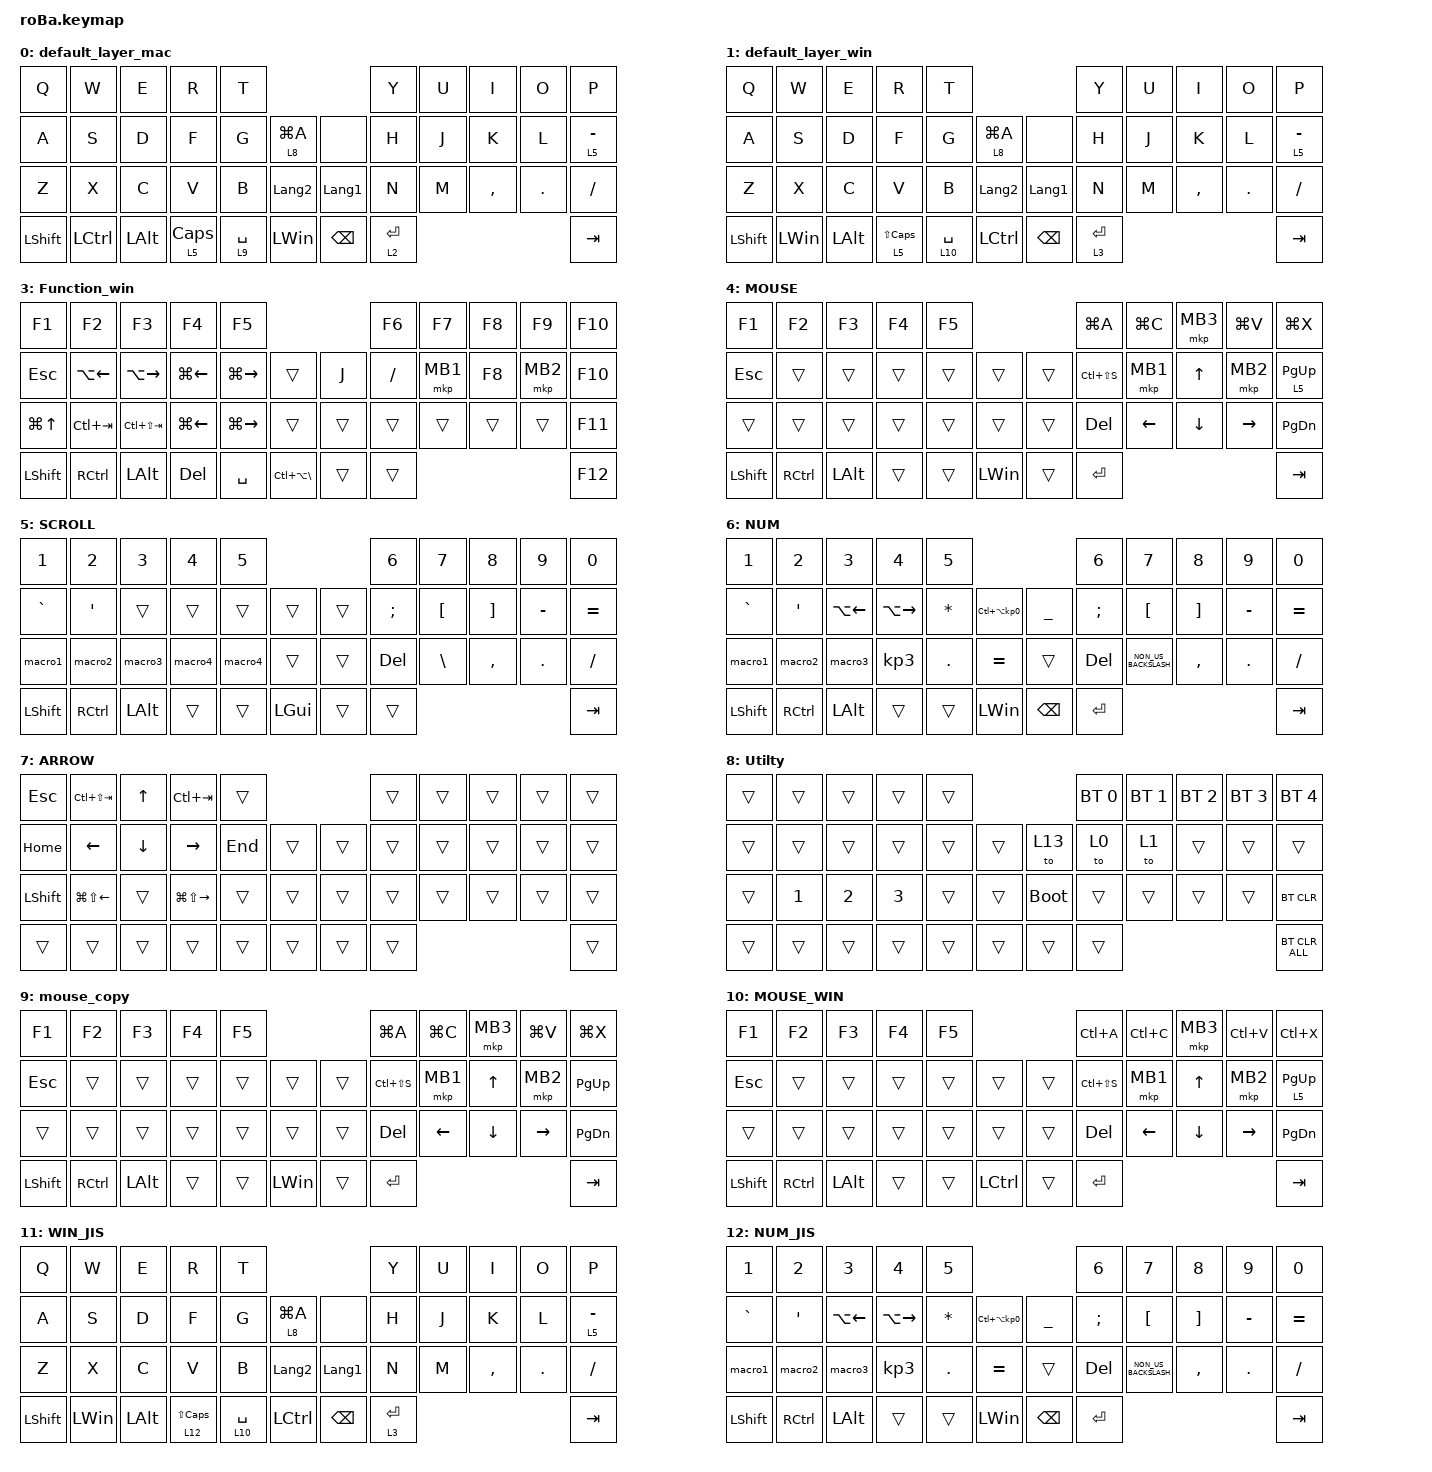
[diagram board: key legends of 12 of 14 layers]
#include <input/processors.dtsi>
#include <behaviors.dtsi>
#include <dt-bindings/zmk/bt.h>
#include <dt-bindings/zmk/keys.h>
#include <dt-bindings/zmk/pointing.h>

&mt {
    flavor = "balanced";
    quick-tap-ms = <0>;
};

&zip_temp_layer { require-prior-idle-ms = <200>; };

&trackball_listener { input-processors = <&zip_temp_layer 4 300>; };

&trackball {
    // automouse-layer = <4>;

    scroll-layers = <5>;

    // arrows {
    //     layers = <3>;
    //     bindings =
    //         <&kp RIGHT_ARROW>,
    //         <&kp LEFT_ARROW>,
    //         <&kp UP_ARROW>,
    //         <&kp DOWN_ARROW>;
    //     tick = <10>;
    //     wait-ms = <5>;
    //     tap-ms = <5>;
    // };
};

/ {
    combos {
        compatible = "zmk,combos";

        tab {
            bindings = <&kp TAB>;
            key-positions = <11 12>;
        };

        shift_tab {
            bindings = <&kp LS(TAB)>;
            key-positions = <12 13>;
        };

        muhennkann {
            bindings = <&to_layer_0 INT_MUHENKAN>;
            key-positions = <11 10>;
        };

        double_quotation {
            bindings = <&kp DOUBLE_QUOTES>;
            key-positions = <20 21>;
        };

        eq {
            bindings = <&kp EQUAL>;
            key-positions = <24 25>;
        };

        JIS_2 {
            bindings = <&kp LEFT_BRACKET>;
            key-positions = <34 1>;
            layers = <12>;
        };

        JIS_3 {
            bindings = <&kp HASH>;
            key-positions = <34 2>;
            layers = <12>;
        };

        JIS_4 {
            bindings = <&kp DOLLAR>;
            key-positions = <34 3>;
            layers = <12>;
        };

        JIS_5 {
            bindings = <&kp PERCENT>;
            key-positions = <34 4>;
            layers = <12>;
        };

        JIS_6 {
            bindings = <&kp EQUAL>;
            key-positions = <34 5>;
            layers = <12>;
        };

        JIS_7 {
            bindings = <&kp CARET>;
            key-positions = <34 6>;
            layers = <12>;
        };

        JIS_8 {
            bindings = <&kp LS(SINGLE_QUOTE)>;
            key-positions = <34 7>;
            layers = <12>;
        };

        JIS_9 {
            bindings = <&kp LS(ASTRK)>;
            key-positions = <34 8>;
            layers = <12>;
        };

        JIS_0 {
            bindings = <&kp LEFT_PARENTHESIS>;
            key-positions = <34 9>;
            layers = <12>;
        };
    };

    macros {
        to_layer_0: to_layer_0 {
            compatible = "zmk,behavior-macro-one-param";
            #binding-cells = <1>;
            bindings = <&to 0 &macro_param_1to1 &kp MACRO_PLACEHOLDER>;
            label = "TO_LAYER_0";
        };

        macro1: macro1 {
            compatible = "zmk,behavior-macro";
            #binding-cells = <0>;
            bindings = <&kp LS(M) &kp O &kp R &kp I &kp H &kp I &kp R &kp O &kp N1 &kp N9 &kp N9 &kp N1>;
            label = "MACRO1";
        };

        macro2: macro2 {
            compatible = "zmk,behavior-macro";
            #binding-cells = <0>;
            bindings = <&kp LS(L) &kp O &kp V &kp E &kp N1 &kp N9 &kp N9 &kp N1 &kp DOT &kp DOT>;
            label = "MACRO2";
        };

        macro3: macro3 {
            compatible = "zmk,behavior-macro";
            #binding-cells = <0>;
            bindings = <&kp L &kp O &kp V &kp E &kp N1 &kp N9 &kp N9 &kp N1>;
            label = "MACRO3";
        };

        macro4: macro4 {
            compatible = "zmk,behavior-macro";
            #binding-cells = <0>;
            bindings = <&kp LS(M) &kp O &kp R &kp I &kp H &kp I &kp R &kp O &kp N1 &kp N9 &kp N9 &kp N1 &kp PERIOD &kp PERIOD>;
            label = "MACRO4";
        };
    };

    behaviors {
        lt_to_layer_0: lt_to_layer_0 {
            compatible = "zmk,behavior-hold-tap";
            label = "LAYER_TAP_TO_0";
            bindings = <&mo>, <&to_layer_0>;

            #binding-cells = <2>;
            tapping-term-ms = <200>;
        };
    };

    keymap {
        compatible = "zmk,keymap";

        default_layer_mac {
            bindings = <
&kp Q           &kp W             &kp E         &kp R       &kp T                                            &kp Y        &kp U  &kp I      &kp O    &kp P
&kp A           &kp S             &kp D         &kp F       &kp G        &lt 8 LG(A)         &none           &kp H        &kp J  &kp K      &kp L    &lt 5 MINUS
&kp Z           &kp X             &kp C         &kp V       &kp B        &kp LANGUAGE_2      &kp LANGUAGE_1  &kp N        &kp M  &kp COMMA  &kp DOT  &kp SLASH
&kp LEFT_SHIFT  &kp LEFT_CONTROL  &kp LEFT_ALT  &lt 5 CAPS  &lt 9 SPACE  &kp LEFT_WIN        &kp BACKSPACE   &lt 2 ENTER                             &kp TAB
            >;

            sensor-bindings = <&inc_dec_kp PAGE_UP PAGE_DOWN>;
        };

        default_layer_win {
            bindings = <
&kp Q           &kp W         &kp E         &kp R           &kp T                                               &kp Y        &kp U  &kp I      &kp O    &kp P
&kp A           &kp S         &kp D         &kp F           &kp G         &lt 8 LG(A)           &none           &kp H        &kp J  &kp K      &kp L    &lt 5 MINUS
&kp Z           &kp X         &kp C         &kp V           &kp B         &kp LANGUAGE_2        &kp LANGUAGE_1  &kp N        &kp M  &kp COMMA  &kp DOT  &kp SLASH
&kp LEFT_SHIFT  &kp LEFT_WIN  &kp LEFT_ALT  &lt 5 LS(CAPS)  &lt 10 SPACE  &kp LEFT_CONTROL      &kp BACKSPACE   &lt 3 ENTER                             &kp TAB
            >;

            sensor-bindings = <&inc_dec_kp PAGE_UP PAGE_DOWN>;
        };

        Function_mac {
            bindings = <
&kp F1                &kp F2            &kp F3             &kp F4         &kp F5                                            &kp F6    &kp F7    &kp F8  &kp F9    &kp F10
&kp ESC               &kp LG(LBKT)      &kp LG(RBKT)       &kp LC(LA(D))  &kp LC(LA(G))  &trans                     &kp J   &kp FSLH  &mkp MB1  &kp F8  &mkp MB2  &kp F10
&kp LA(LC(LS(FSLH)))  &kp LA(LG(LEFT))  &kp LA(LG(RIGHT))  &kp LA(LC(E))  &kp LC(LA(T))  &trans                     &trans  &trans    &trans    &trans  &trans    &kp F11
&kp LSHFT             &kp RCTRL         &kp LEFT_ALT       &kp DELETE     &kp SPACE      &kp LC(LA(BACKSLASH))      &trans  &trans                                &kp F12
            >;
        };

        Function_win {
            bindings = <
&kp F1            &kp F2        &kp F3           &kp F4        &kp F5                                            &kp F6    &kp F7    &kp F8  &kp F9    &kp F10
&kp ESC           &kp LA(LEFT)  &kp LA(RIGHT)    &kp LG(LEFT)  &kp LG(RIGHT)  &trans                     &kp J   &kp FSLH  &mkp MB1  &kp F8  &mkp MB2  &kp F10
&kp LG(UP_ARROW)  &kp LC(TAB)   &kp LC(LS(TAB))  &kp LG(LEFT)  &kp LG(RIGHT)  &trans                     &trans  &trans    &trans    &trans  &trans    &kp F11
&kp LSHFT         &kp RCTRL     &kp LEFT_ALT     &kp DELETE    &kp SPACE      &kp LC(LA(BACKSLASH))      &trans  &trans                                &kp F12
            >;
        };

        MOUSE {
            bindings = <
&kp F1          &kp F2     &kp F3        &kp F4  &kp F5                            &kp LG(A)      &kp LG(C)  &mkp MB3  &kp LG(V)  &kp LG(X)
&kp ESC         &trans     &trans        &trans  &trans  &trans            &trans  &kp LC(LS(S))  &mkp MB1   &kp UP    &mkp MB2   &lt 5 PAGE_UP
&trans          &trans     &trans        &trans  &trans  &trans            &trans  &kp DELETE     &kp LEFT   &kp DOWN  &kp RIGHT  &kp PAGE_DOWN
&kp LEFT_SHIFT  &kp RCTRL  &kp LEFT_ALT  &trans  &trans  &kp LEFT_WIN      &trans  &kp ENTER                                      &kp TAB
            >;
        };

        SCROLL {
            bindings = <
&kp N1     &kp N2     &kp N3        &kp N4   &kp N5                         &kp N6      &kp N7         &kp N8     &kp N9     &kp N0
&kp GRAVE  &kp SQT    &trans        &trans   &trans   &trans        &trans  &kp SEMI    &kp LBKT       &kp RBKT   &kp MINUS  &kp EQUAL
&macro1    &macro2    &macro3       &macro4  &macro4  &trans        &trans  &kp DELETE  &kp BACKSLASH  &kp COMMA  &kp DOT    &kp FSLH
&kp LSHFT  &kp RCTRL  &kp LEFT_ALT  &trans   &trans   &kp LGUI      &trans  &trans                                           &kp TAB
            >;
        };

        NUM {
            bindings = <
&kp NUMBER_1    &kp NUMBER_2  &kp NUMBER_3  &kp NUMBER_4     &kp N5                                                     &kp NUMBER_6   &kp N7                &kp N8             &kp N9      &kp N0
&kp GRAVE       &kp SQT       &kp LA(LEFT)  &kp LA(RIGHT)    &kp ASTERISK  &kp LC(LA(KP_NUMBER_0))      &kp UNDERSCORE  &kp SEMICOLON  &kp LEFT_BRACKET      &kp RIGHT_BRACKET  &kp MINUS   &kp EQUAL
&macro1         &macro2       &macro3       &kp KP_NUMBER_3  &kp PERIOD    &kp EQUAL                    &trans          &kp DEL        &kp NON_US_BACKSLASH  &kp COMMA          &kp PERIOD  &kp SLASH
&kp LEFT_SHIFT  &kp RCTRL     &kp LEFT_ALT  &trans           &trans        &kp LEFT_WIN                 &kp BACKSPACE   &kp ENTER                                                           &kp TAB
            >;
        };

        ARROW {
            bindings = <
&kp ESCAPE      &kp LC(LS(TAB))         &kp UP_ARROW    &kp LC(TAB)              &trans                       &trans  &trans  &trans  &trans  &trans
&kp HOME        &kp LEFT_ARROW          &kp DOWN_ARROW  &kp RIGHT_ARROW          &kp END  &trans      &trans  &trans  &trans  &trans  &trans  &trans
&kp LEFT_SHIFT  &kp LG(LS(LEFT_ARROW))  &trans          &kp LG(LS(RIGHT_ARROW))  &trans   &trans      &trans  &trans  &trans  &trans  &trans  &trans
&trans          &trans                  &trans          &trans                   &trans   &trans      &trans  &trans                          &trans
            >;

            sensor-bindings = <&inc_dec_kp LC(PAGE_UP) LC(PAGE_DOWN)>;
        };

        Utilty {
            bindings = <
&trans  &trans        &trans        &trans        &trans                           &bt BT_SEL 0  &bt BT_SEL 1  &bt BT_SEL 2  &bt BT_SEL 3  &bt BT_SEL 4
&trans  &trans        &trans        &trans        &trans  &trans      &to 13       &to 0         &to 1         &trans        &trans        &trans
&trans  &kp NUMBER_1  &kp NUMBER_2  &kp NUMBER_3  &trans  &trans      &bootloader  &trans        &trans        &trans        &trans        &bt BT_CLR
&trans  &trans        &trans        &trans        &trans  &trans      &trans       &trans                                                  &bt BT_CLR_ALL
            >;
        };

        mouse_copy {
            bindings = <
&kp F1          &kp F2     &kp F3        &kp F4  &kp F5                            &kp LG(A)      &kp LG(C)  &mkp MB3  &kp LG(V)  &kp LG(X)
&kp ESC         &trans     &trans        &trans  &trans  &trans            &trans  &kp LC(LS(S))  &mkp MB1   &kp UP    &mkp MB2   &kp PAGE_UP
&trans          &trans     &trans        &trans  &trans  &trans            &trans  &kp DELETE     &kp LEFT   &kp DOWN  &kp RIGHT  &kp PAGE_DOWN
&kp LEFT_SHIFT  &kp RCTRL  &kp LEFT_ALT  &trans  &trans  &kp LEFT_WIN      &trans  &kp ENTER                                      &kp TAB
            >;
        };

        MOUSE_WIN {
            bindings = <
&kp F1          &kp F2     &kp F3        &kp F4  &kp F5                                &kp LC(A)      &kp LC(C)  &mkp MB3  &kp LC(V)  &kp LC(X)
&kp ESC         &trans     &trans        &trans  &trans  &trans                &trans  &kp LC(LS(S))  &mkp MB1   &kp UP    &mkp MB2   &lt 5 PAGE_UP
&trans          &trans     &trans        &trans  &trans  &trans                &trans  &kp DELETE     &kp LEFT   &kp DOWN  &kp RIGHT  &kp PAGE_DOWN
&kp LEFT_SHIFT  &kp RCTRL  &kp LEFT_ALT  &trans  &trans  &kp LEFT_CONTROL      &trans  &kp ENTER                                      &kp TAB
            >;
        };

        WIN_JIS {
            bindings = <
&kp Q           &kp W         &kp E         &kp R            &kp T                                               &kp Y        &kp U  &kp I      &kp O    &kp P
&kp A           &kp S         &kp D         &kp F            &kp G         &lt 8 LG(A)           &none           &kp H        &kp J  &kp K      &kp L    &lt 5 MINUS
&kp Z           &kp X         &kp C         &kp V            &kp B         &kp LANGUAGE_2        &kp LANGUAGE_1  &kp N        &kp M  &kp COMMA  &kp DOT  &kp SLASH
&kp LEFT_SHIFT  &kp LEFT_WIN  &kp LEFT_ALT  &lt 12 LS(CAPS)  &lt 10 SPACE  &kp LEFT_CONTROL      &kp BACKSPACE   &lt 3 ENTER                             &kp TAB
            >;

            sensor-bindings = <&inc_dec_kp PAGE_UP PAGE_DOWN>;
        };

        NUM_JIS {
            bindings = <
&kp NUMBER_1    &kp NUMBER_2  &kp NUMBER_3  &kp NUMBER_4     &kp N5                                                     &kp NUMBER_6   &kp N7                &kp N8             &kp N9      &kp N0
&kp GRAVE       &kp SQT       &kp LA(LEFT)  &kp LA(RIGHT)    &kp ASTERISK  &kp LC(LA(KP_NUMBER_0))      &kp UNDERSCORE  &kp SEMICOLON  &kp LEFT_BRACKET      &kp RIGHT_BRACKET  &kp MINUS   &kp EQUAL
&macro1         &macro2       &macro3       &kp KP_NUMBER_3  &kp PERIOD    &kp EQUAL                    &trans          &kp DEL        &kp NON_US_BACKSLASH  &kp COMMA          &kp PERIOD  &kp SLASH
&kp LEFT_SHIFT  &kp RCTRL     &kp LEFT_ALT  &trans           &trans        &kp LEFT_WIN                 &kp BACKSPACE   &kp ENTER                                                           &kp TAB
            >;
        };

        game {
            bindings = <
&kp ESCAPE  &kp Q  &kp W  &kp E   &kp R                          &trans  &trans  &trans  &trans  &trans
&kp LSHFT   &kp A  &kp S  &kp D   &kp F      &mo 8       &trans  &trans  &trans  &trans  &trans  &trans
&kp F1      &kp X  &kp G  &kp H   &kp B      &kp N1      &trans  &trans  &trans  &trans  &trans  &trans
&kp TAB     &kp M  &kp Z  &kp F2  &kp SPACE  &kp G       &trans  &trans                          &trans
            >;

            sensor-bindings = <&inc_dec_kp PAGE_UP PAGE_DOWN>;
        };
    };
};
